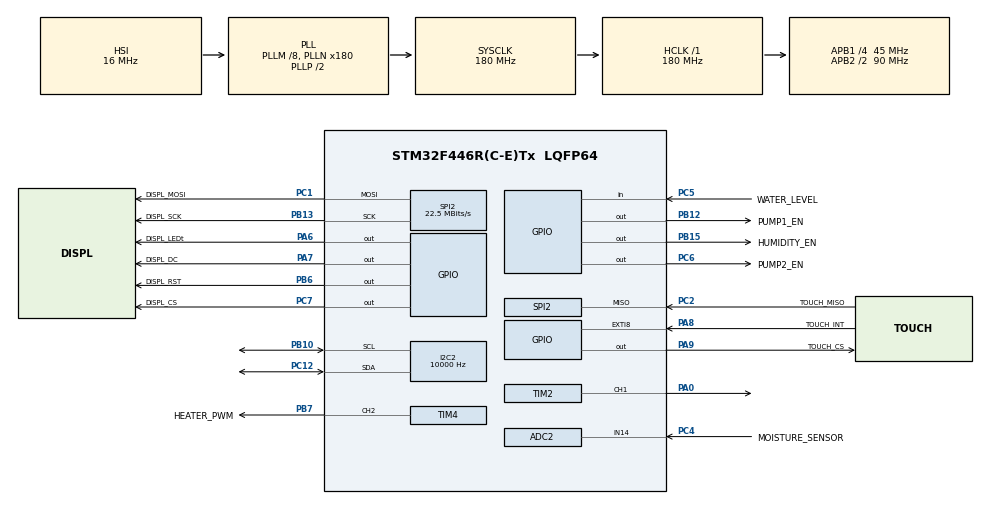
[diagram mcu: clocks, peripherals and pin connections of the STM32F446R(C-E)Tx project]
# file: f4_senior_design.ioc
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ADC2.Channel-0\#ChannelRegularConversion=ADC_CHANNEL_14
ADC2.ContinuousConvMode=ENABLE
ADC2.InjNumberOfConversion=0
ADC2.NbrOfConversionFlag=1
ADC2.Rank-0\#ChannelRegularConversion=1
ADC2.SamplingTime-0\#ChannelRegularConversion=ADC_SAMPLETIME_3CYCLES
Dma.ADC2.1.Direction=DMA_PERIPH_TO_MEMORY
Dma.ADC2.1.FIFOMode=DMA_FIFOMODE_DISABLE
Dma.ADC2.1.Instance=DMA2_Stream2
Dma.ADC2.1.MemDataAlignment=DMA_MDATAALIGN_HALFWORD
Dma.ADC2.1.MemInc=DMA_MINC_ENABLE
Dma.ADC2.1.Mode=DMA_CIRCULAR
Dma.ADC2.1.PeriphDataAlignment=DMA_PDATAALIGN_HALFWORD
Dma.ADC2.1.PeriphInc=DMA_PINC_DISABLE
Dma.ADC2.1.Priority=DMA_PRIORITY_LOW
Dma.Request0=SPI2_TX
Dma.Request1=ADC2
Dma.SPI2_TX.0.Direction=DMA_MEMORY_TO_PERIPH
Dma.SPI2_TX.0.FIFOMode=DMA_FIFOMODE_DISABLE
Dma.SPI2_TX.0.Instance=DMA1_Stream4
Dma.SPI2_TX.0.MemDataAlignment=DMA_MDATAALIGN_BYTE
Dma.SPI2_TX.0.MemInc=DMA_MINC_ENABLE
Dma.SPI2_TX.0.Mode=DMA_NORMAL
Dma.SPI2_TX.0.PeriphDataAlignment=DMA_PDATAALIGN_BYTE
Dma.SPI2_TX.0.PeriphInc=DMA_PINC_DISABLE
Dma.SPI2_TX.0.Priority=DMA_PRIORITY_LOW
I2C2.ClockSpeed=10000
I2C2.I2C_Mode=I2C_Standard
Mcu.Family=STM32F4
Mcu.Name=STM32F446R(C-E)Tx
Mcu.Package=LQFP64
NVIC.DMA1_Stream4_IRQn=true\:0\:0\:false\:false\:true\:false\:true\:true
NVIC.DMA2_Stream2_IRQn=true\:0\:0\:false\:false\:true\:false\:true\:true
NVIC.EXTI9_5_IRQn=true\:0\:0\:false\:false\:true\:true\:true\:true
NVIC.PriorityGroup=NVIC_PRIORITYGROUP_4
NVIC.SPI2_IRQn=true\:0\:0\:false\:false\:true\:true\:true\:true
NVIC.TIM3_IRQn=true\:0\:0\:false\:false\:true\:true\:true\:true
NVIC.TIM4_IRQn=true\:0\:0\:false\:false\:true\:true\:true\:true
PA0-WKUP.Signal=S_TIM2_CH1_ETR
PA13.GPIO_Label=TMS
PA13.Mode=Serial_Wire
PA13.Signal=SYS_JTMS-SWDIO
PA14.GPIO_Label=TCK
PA14.Mode=Serial_Wire
PA14.Signal=SYS_JTCK-SWCLK
PA6.GPIO_Label=DISPL_LED\t
PA6.Signal=GPIO_Output
PA7.GPIO_Label=DISPL_DC
PA7.Signal=GPIO_Output
PA8.GPIO_Label=TOUCH_INT
PA8.GPIO_ModeDefaultEXTI=GPIO_MODE_IT_FALLING
PA8.GPIO_PuPd=GPIO_PULLUP
PA8.Signal=GPXTI8
PA9.GPIO_Label=TOUCH_CS
PA9.PinState=GPIO_PIN_SET
PA9.Signal=GPIO_Output
PB10.GPIO_Pu=GPIO_NOPULL
PB10.Mode=I2C
PB10.Signal=I2C2_SCL
PB12.GPIO_Label=PUMP1_EN
PB12.Signal=GPIO_Output
PB13.GPIO_Label=DISPL_SCK
PB13.Mode=Full_Duplex_Master
PB13.Signal=SPI2_SCK
PB15.GPIO_Label=HUMIDITY_EN
PB15.Signal=GPIO_Output
PB6.GPIO_Label=DISPL_RST
PB6.Signal=GPIO_Output
PB7.GPIO_Label=HEATER_PWM
PB7.Signal=S_TIM4_CH2
PB8.Signal=I2C1_SCL
PB9.Signal=I2C1_SDA
PC1.GPIO_Label=DISPL_MOSI
PC1.Mode=Full_Duplex_Master
PC1.Signal=SPI2_MOSI
PC12.GPIO_Pu=GPIO_NOPULL
PC12.Mode=I2C
PC12.Signal=I2C2_SDA
PC14-OSC32_IN.Mode=LSE-External-Oscillator
PC14-OSC32_IN.Signal=RCC_OSC32_IN
PC15-OSC32_OUT.Mode=LSE-External-Oscillator
PC15-OSC32_OUT.Signal=RCC_OSC32_OUT
PC2.GPIO_Label=TOUCH_MISO
PC2.Mode=Full_Duplex_Master
PC2.Signal=SPI2_MISO
PC4.GPIO_Label=MOISTURE_SENSOR
PC4.Signal=ADCx_IN14
PC5.GPIO_Label=WATER_LEVEL
PC5.Signal=GPIO_Input
PC6.GPIO_Label=PUMP2_EN
PC6.GPIO_Speed=GPIO_SPEED_FREQ_LOW
PC6.Signal=GPIO_Output
PC7.GPIO_Label=DISPL_CS
PC7.PinState=GPIO_PIN_SET
PC7.Signal=GPIO_Output
ProjectManager.HeapSize=0x200
ProjectManager.StackSize=0x400
ProjectManager.TargetToolchain=STM32CubeIDE
RCC.AHBFreq_Value=180000000
RCC.APB1CLKDivider=RCC_HCLK_DIV4
RCC.APB1Freq_Value=45000000
RCC.APB1TimFreq_Value=90000000
RCC.APB2CLKDivider=RCC_HCLK_DIV2
RCC.APB2Freq_Value=90000000
RCC.APB2TimFreq_Value=180000000
RCC.CortexFreq_Value=180000000
RCC.FLatency-AdvancedSettings=FLASH_LATENCY_5
RCC.HCLKFreq_Value=180000000
RCC.HSE_VALUE=8000000
RCC.HSI_VALUE=16000000
RCC.PLLM=8
RCC.PLLN=180
RCC.SYSCLKFreq_VALUE=180000000
RCC.SYSCLKSource=RCC_SYSCLKSOURCE_PLLCLK
RCC.USBFreq_Value=180000000
RCC.VCOOutputFreq_Value=360000000
SH.ADCx_IN14.0=ADC2_IN14,IN14
SH.S_TIM2_CH1_ETR.0=TIM2_CH1,PWM Generation1 CH1
SH.S_TIM4_CH2.0=TIM4_CH2,PWM Generation2 CH2
SPI2.BaudRatePrescaler=SPI_BAUDRATEPRESCALER_2
SPI2.CalculateBaudRate=22.5 MBits/s
SPI2.Direction=SPI_DIRECTION_2LINES
SPI2.Mode=SPI_MODE_MASTER
SPI2.VirtualType=VM_MASTER
STMicroelectronics.X-CUBE-TOUCHGFX.4.24.2.ApplicationCcGraphicsJjApplication=TouchGFXOoGenerator
STMicroelectronics.X-CUBE-TOUCHGFX.4.24.2.tgfx_block_size=2880
STMicroelectronics.X-CUBE-TOUCHGFX.4.24.2.tgfx_buffering_strategy=Partial
STMicroelectronics.X-CUBE-TOUCHGFX.4.24.2.tgfx_custom_height=480
STMicroelectronics.X-CUBE-TOUCHGFX.4.24.2.tgfx_custom_width=320
STMicroelectronics.X-CUBE-TOUCHGFX.4.24.2_IsPackSelfContextualization=true
TIM2.Channel-PWM\ Generation1\ CH1=TIM_CHANNEL_1
TIM2.Period=29999
TIM2.Prescaler=59999
TIM3.Period=299
TIM3.Prescaler=9999
TIM4.Channel-PWM\ Generation2\ CH2=TIM_CHANNEL_2
TIM4.Period=19
TIM4.Prescaler=44999
VP_CRC_VS_CRC.Mode=CRC_Activate
VP_STMicroelectronics.X-CUBE-TOUCHGFX_VS_GraphicsJjApplication_4.24.2.Mode=GraphicsJjApplication
VP_TIM2_VS_ClockSourceINT.Mode=Internal
VP_TIM3_VS_ClockSourceINT.Mode=Internal
VP_TIM4_VS_ClockSourceINT.Mode=Internal
board=NUCLEO-F446RE

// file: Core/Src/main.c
/* USER CODE BEGIN Header */
	/**
	  ******************************************************************************
	  * @file           : main.c
	  * @brief          : Main program body
	  ******************************************************************************
	  * @attention
	  *
	  * Copyright (c) 2025 STMicroelectronics.
	  * All rights reserved.
	  *
	  * This software is licensed under terms that can be found in the LICENSE file
	  * in the root directory of this software component.
	  * If no LICENSE file comes with this software, it is provided AS-IS.
	  *
	  ******************************************************************************
	  */
/* USER CODE END Header */
#include "main.h"
#include "app_touchgfx.h"

ADC_HandleTypeDef hadc2;
DMA_HandleTypeDef hdma_adc2;

CRC_HandleTypeDef hcrc;

I2C_HandleTypeDef hi2c2;

SPI_HandleTypeDef hspi2;
DMA_HandleTypeDef hdma_spi2_tx;

TIM_HandleTypeDef htim2;
TIM_HandleTypeDef htim3;
TIM_HandleTypeDef htim4;

/* USER CODE BEGIN PV */
	uint32_t value_adc;
	float raw_temp;
	float raw_hum;
	float temp;
	float hum;
	float temp_set_point = 20;
	float humidity_set_point = 50;
	int lights_set_point = 8;
	uint8_t i2c_return[8];
	uint8_t i2c_buffer[3] = {0x03, 0x00, 0x04};

/* USER CODE END PV */

void SystemClock_Config(void);
static void MX_GPIO_Init(void);
static void MX_DMA_Init(void);
static void MX_SPI2_Init(void);
static void MX_CRC_Init(void);
static void MX_TIM3_Init(void);
static void MX_TIM2_Init(void);
static void MX_I2C2_Init(void);
static void MX_TIM4_Init(void);
static void MX_ADC2_Init(void);

int main(void)
{

  /* MCU Configuration--------------------------------------------------------*/

  /* Reset of all peripherals, Initializes the Flash interface and the Systick. */
  HAL_Init();

  /* Configure the system clock */
  SystemClock_Config();

  /* Initialize all configured peripherals */
  MX_GPIO_Init();
  MX_DMA_Init();
  MX_SPI2_Init();
  MX_CRC_Init();
  MX_TIM3_Init();
  MX_TIM2_Init();
  MX_I2C2_Init();
  MX_TIM4_Init();
  MX_ADC2_Init();
  MX_TouchGFX_Init();
  /* USER CODE BEGIN 2 */

	  HAL_TIM_PWM_Init(&htim2);

	  Displ_Init(Displ_Orientat_0);			// initialize display controller - set orientation parameter as per TouchGFX setup
	  touchgfxSignalVSync();
	  Displ_Init(Displ_Orientat_0);			// initialize display controller - set orientation parameter as per TouchGFX setup
	  touchgfxSignalVSync();

	  Displ_BackLight('I');  					// initialize backlight
	  HAL_TIM_Base_Start_IT(&TGFX_T);			// start TouchGFX tick timer
	  HAL_ADC_Start_DMA(&hadc2,(uint32_t*)&value_adc,1);
	  HAL_TIM_PWM_Start(&htim2,TIM_CHANNEL_1);

	  HAL_TIM_PWM_Start(&htim4, TIM_CHANNEL_2);
	  htim4.Instance->CCR2 = 10;
	  htim2.Instance->CCR1 = 15000;

  /* USER CODE END 2 */

  /* Infinite loop */
  /* USER CODE BEGIN WHILE */
//	  while(HAL_I2C_IsDeviceReady(&hi2c1, 0xB8,1, HAL_MAX_DELAY) != HAL_OK){
//
//	  }

	  //HAL_GPIO_WritePin(HUMIDITY_EN_GPIO_Port, HUMIDITY_EN_Pin,1);

	  while (1)
	  {
//		  HAL_GPIO_WritePin(GPIOA, GPIO_PIN_0,1);
//		  HAL_GPIO_WritePin(PUMP1_EN_GPIO_Port, PUMP1_EN_Pin, 0);
//		  HAL_GPIO_WritePin(PUMP2_EN_GPIO_Port, PUMP2_EN_Pin, 0);
//	  	  HAL_GPIO_WritePin(HUMIDITY_EN_GPIO_Port, HUMIDITY_EN_Pin,0);
//
//		  HAL_Delay(10000);
//		  HAL_GPIO_WritePin(PUMP1_EN_GPIO_Port, PUMP1_EN_Pin, 1);
//		  HAL_GPIO_WritePin(PUMP2_EN_GPIO_Port, PUMP2_EN_Pin, 1);
//	  	  HAL_GPIO_WritePin(HUMIDITY_EN_GPIO_Port, HUMIDITY_EN_Pin,1);
//
//		  HAL_Delay(10000);

		  if (HAL_GPIO_ReadPin(WATER_LEVEL_GPIO_Port, WATER_LEVEL_Pin)){
			  HAL_GPIO_WritePin(PUMP1_EN_GPIO_Port, PUMP1_EN_Pin, 1);
			  HAL_GPIO_WritePin(PUMP2_EN_GPIO_Port, PUMP2_EN_Pin, 1);
		  }
		  else{
			  HAL_GPIO_WritePin(PUMP1_EN_GPIO_Port, PUMP1_EN_Pin, 0);
			  HAL_GPIO_WritePin(PUMP2_EN_GPIO_Port, PUMP2_EN_Pin, 0);
		  }

		  HAL_ADC_Start_DMA(&hadc2,(uint32_t*)&value_adc,1); //Read Soil Moisture

		  HAL_I2C_Master_Transmit (&hi2c2, 0xB8, i2c_buffer, 3, 100);
		  HAL_I2C_Master_Receive (&hi2c2, 0xB9, i2c_return, 8, 100);

		  temp = ((i2c_return[4] << 8) + i2c_return[5]);
		  hum = ((i2c_return[2] << 8) + i2c_return[3]);
		  temp = floor(temp)/10.0;
		  hum = floor(hum)/10.0;

//		  raw_temp = ((i2c_return[4] << 8) + i2c_return[5]);
//		  raw_hum = ((i2c_return[2] << 8) + i2c_return[3]);
//		  raw_temp = floor(raw_temp)/10.0;
//		  raw_hum = floor(raw_hum)/10.0;
//
//		  if (raw_temp > 0 && raw_temp < 100){
//			  temp = raw_temp;
//		  }
//
//		  if (raw_hum > 0 && raw_hum < 100){
//		  			  hum = raw_hum;
//		  		  }

		  if (hum <=(40)){
			  HAL_GPIO_WritePin(HUMIDITY_EN_GPIO_Port, HUMIDITY_EN_Pin,1);
		  }
		  if (hum >=(60)){
			  HAL_GPIO_WritePin(HUMIDITY_EN_GPIO_Port, HUMIDITY_EN_Pin,0);
			  }
//
//		  //htim4.Instance->CCR2 = (value_adc/4096.0) * 100;
//		  if (temp < 23){
//			  htim4.Instance->CCR2 = 10;
//		  }
//		  if (temp > 24){
//			  htim4.Instance->CCR2 = 0;
//		  		  }
////		  else{
////			  htim2.Instance->CCR1 = 0;
////
////		  }
//		  //HAL_GPIO_WritePin(GPIOA, GPIO_PIN_10,1);
//

//
//	//	  for (int i = 0; i <= 8; i++){
//	//		  htim2.Instance->CCR1 = 4096 - (512 * i); //100
//	//		  HAL_Delay(2000);
//	//
//	//	  }
//
//		  //HAL_Delay(100);
//		  //HAL_I2C_Master_Receive (&hi2c2, 0xB9, data, 5, 100);
//
//		  //HAL_I2C_Mem_Read (&hi2c2, 0xB8, 0x00, 0, value_humidity_high, 5, 1000);
//		  //HAL_I2C_Master_Transmit (I2C_HandleTypeDef * hi2c, uint16_t DevAddress, uint8_t* pData, uint16_t Size, uint32_t Timeout);
//		  //HAL_I2C_Master_Receive (I2C_HandleTypeDef * hi2c, uint16_t DevAddress, uint8_t* pData, uint16_t Size, uint32_t Timeout);
//	//	  HAL_I2C_Mem_Write (I2C_HandleTypeDef * hi2c, uint16_t DevAddress, uint16_t MemAddress, uint16_t MemAddSize, uint8_t * pData, uint16_t Size, uint32_t Timeout);
//
//
//		  //HAL_I2C_Mem_Read (I2C_HandleTypeDef * hi2c, uint16_t DevAddress, uint16_t MemAddress, uint16_t MemAddSize, uint8_t * pData, uint16_t Size, uint32_t Timeout);
//
//
//
    /* USER CODE END WHILE */

  MX_TouchGFX_Process();
	  }
}

void SystemClock_Config(void)
{
  RCC_OscInitTypeDef RCC_OscInitStruct = {0};
  RCC_ClkInitTypeDef RCC_ClkInitStruct = {0};

  /** Configure the main internal regulator output voltage
  */
  __HAL_RCC_PWR_CLK_ENABLE();
  __HAL_PWR_VOLTAGESCALING_CONFIG(PWR_REGULATOR_VOLTAGE_SCALE1);

  /** Initializes the RCC Oscillators according to the specified parameters
  * in the RCC_OscInitTypeDef structure.
  */
  RCC_OscInitStruct.OscillatorType = RCC_OSCILLATORTYPE_HSI;
  RCC_OscInitStruct.HSIState = RCC_HSI_ON;
  RCC_OscInitStruct.HSICalibrationValue = RCC_HSICALIBRATION_DEFAULT;
  RCC_OscInitStruct.PLL.PLLState = RCC_PLL_ON;
  RCC_OscInitStruct.PLL.PLLSource = RCC_PLLSOURCE_HSI;
  RCC_OscInitStruct.PLL.PLLM = 8;
  RCC_OscInitStruct.PLL.PLLN = 180;
  RCC_OscInitStruct.PLL.PLLP = RCC_PLLP_DIV2;
  RCC_OscInitStruct.PLL.PLLQ = 2;
  RCC_OscInitStruct.PLL.PLLR = 2;
  if (HAL_RCC_OscConfig(&RCC_OscInitStruct) != HAL_OK)
  {
    Error_Handler();
  }

  /** Activate the Over-Drive mode
  */
  if (HAL_PWREx_EnableOverDrive() != HAL_OK)
  {
    Error_Handler();
  }

  /** Initializes the CPU, AHB and APB buses clocks
  */
  RCC_ClkInitStruct.ClockType = RCC_CLOCKTYPE_HCLK|RCC_CLOCKTYPE_SYSCLK
                              |RCC_CLOCKTYPE_PCLK1|RCC_CLOCKTYPE_PCLK2;
  RCC_ClkInitStruct.SYSCLKSource = RCC_SYSCLKSOURCE_PLLCLK;
  RCC_ClkInitStruct.AHBCLKDivider = RCC_SYSCLK_DIV1;
  RCC_ClkInitStruct.APB1CLKDivider = RCC_HCLK_DIV4;
  RCC_ClkInitStruct.APB2CLKDivider = RCC_HCLK_DIV2;

  if (HAL_RCC_ClockConfig(&RCC_ClkInitStruct, FLASH_LATENCY_5) != HAL_OK)
  {
    Error_Handler();
  }
}

static void MX_ADC2_Init(void)
{

  ADC_ChannelConfTypeDef sConfig = {0};

  /** Configure the global features of the ADC (Clock, Resolution, Data Alignment and number of conversion)
  */
  hadc2.Instance = ADC2;
  hadc2.Init.ClockPrescaler = ADC_CLOCK_SYNC_PCLK_DIV4;
  hadc2.Init.Resolution = ADC_RESOLUTION_12B;
  hadc2.Init.ScanConvMode = DISABLE;
  hadc2.Init.ContinuousConvMode = ENABLE;
  hadc2.Init.DiscontinuousConvMode = DISABLE;
  hadc2.Init.ExternalTrigConvEdge = ADC_EXTERNALTRIGCONVEDGE_NONE;
  hadc2.Init.ExternalTrigConv = ADC_SOFTWARE_START;
  hadc2.Init.DataAlign = ADC_DATAALIGN_RIGHT;
  hadc2.Init.NbrOfConversion = 1;
  hadc2.Init.DMAContinuousRequests = DISABLE;
  hadc2.Init.EOCSelection = ADC_EOC_SINGLE_CONV;
  if (HAL_ADC_Init(&hadc2) != HAL_OK)
  {
    Error_Handler();
  }

  /** Configure for the selected ADC regular channel its corresponding rank in the sequencer and its sample time.
  */
  sConfig.Channel = ADC_CHANNEL_14;
  sConfig.Rank = 1;
  sConfig.SamplingTime = ADC_SAMPLETIME_3CYCLES;
  if (HAL_ADC_ConfigChannel(&hadc2, &sConfig) != HAL_OK)
  {
    Error_Handler();
  }

}

static void MX_CRC_Init(void)
{

  hcrc.Instance = CRC;
  if (HAL_CRC_Init(&hcrc) != HAL_OK)
  {
    Error_Handler();
  }

}

static void MX_I2C2_Init(void)
{

  hi2c2.Instance = I2C2;
  hi2c2.Init.ClockSpeed = 100000;
  hi2c2.Init.DutyCycle = I2C_DUTYCYCLE_2;
  hi2c2.Init.OwnAddress1 = 0;
  hi2c2.Init.AddressingMode = I2C_ADDRESSINGMODE_7BIT;
  hi2c2.Init.DualAddressMode = I2C_DUALADDRESS_DISABLE;
  hi2c2.Init.OwnAddress2 = 0;
  hi2c2.Init.GeneralCallMode = I2C_GENERALCALL_DISABLE;
  hi2c2.Init.NoStretchMode = I2C_NOSTRETCH_DISABLE;
  if (HAL_I2C_Init(&hi2c2) != HAL_OK)
  {
    Error_Handler();
  }

}

static void MX_SPI2_Init(void)
{

  /* SPI2 parameter configuration*/
  hspi2.Instance = SPI2;
  hspi2.Init.Mode = SPI_MODE_MASTER;
  hspi2.Init.Direction = SPI_DIRECTION_2LINES;
  hspi2.Init.DataSize = SPI_DATASIZE_8BIT;
  hspi2.Init.CLKPolarity = SPI_POLARITY_LOW;
  hspi2.Init.CLKPhase = SPI_PHASE_1EDGE;
  hspi2.Init.NSS = SPI_NSS_SOFT;
  hspi2.Init.BaudRatePrescaler = SPI_BAUDRATEPRESCALER_2;
  hspi2.Init.FirstBit = SPI_FIRSTBIT_MSB;
  hspi2.Init.TIMode = SPI_TIMODE_DISABLE;
  hspi2.Init.CRCCalculation = SPI_CRCCALCULATION_DISABLE;
  hspi2.Init.CRCPolynomial = 10;
  if (HAL_SPI_Init(&hspi2) != HAL_OK)
  {
    Error_Handler();
  }

}

static void MX_TIM2_Init(void)
{

  TIM_ClockConfigTypeDef sClockSourceConfig = {0};
  TIM_MasterConfigTypeDef sMasterConfig = {0};
  TIM_OC_InitTypeDef sConfigOC = {0};

  htim2.Instance = TIM2;
  htim2.Init.Prescaler = 59999;
  htim2.Init.CounterMode = TIM_COUNTERMODE_UP;
  htim2.Init.Period = 29999;
  htim2.Init.ClockDivision = TIM_CLOCKDIVISION_DIV1;
  htim2.Init.AutoReloadPreload = TIM_AUTORELOAD_PRELOAD_DISABLE;
  if (HAL_TIM_Base_Init(&htim2) != HAL_OK)
  {
    Error_Handler();
  }
  sClockSourceConfig.ClockSource = TIM_CLOCKSOURCE_INTERNAL;
  if (HAL_TIM_ConfigClockSource(&htim2, &sClockSourceConfig) != HAL_OK)
  {
    Error_Handler();
  }
  if (HAL_TIM_PWM_Init(&htim2) != HAL_OK)
  {
    Error_Handler();
  }
  sMasterConfig.MasterOutputTrigger = TIM_TRGO_RESET;
  sMasterConfig.MasterSlaveMode = TIM_MASTERSLAVEMODE_DISABLE;
  if (HAL_TIMEx_MasterConfigSynchronization(&htim2, &sMasterConfig) != HAL_OK)
  {
    Error_Handler();
  }
  sConfigOC.OCMode = TIM_OCMODE_PWM1;
  sConfigOC.Pulse = 0;
  sConfigOC.OCPolarity = TIM_OCPOLARITY_HIGH;
  sConfigOC.OCFastMode = TIM_OCFAST_DISABLE;
  if (HAL_TIM_PWM_ConfigChannel(&htim2, &sConfigOC, TIM_CHANNEL_1) != HAL_OK)
  {
    Error_Handler();
  }
  HAL_TIM_MspPostInit(&htim2);

}

static void MX_TIM3_Init(void)
{

  TIM_ClockConfigTypeDef sClockSourceConfig = {0};
  TIM_MasterConfigTypeDef sMasterConfig = {0};

  htim3.Instance = TIM3;
  htim3.Init.Prescaler = 9999;
  htim3.Init.CounterMode = TIM_COUNTERMODE_UP;
  htim3.Init.Period = 299;
  htim3.Init.ClockDivision = TIM_CLOCKDIVISION_DIV1;
  htim3.Init.AutoReloadPreload = TIM_AUTORELOAD_PRELOAD_DISABLE;
  if (HAL_TIM_Base_Init(&htim3) != HAL_OK)
  {
    Error_Handler();
  }
  sClockSourceConfig.ClockSource = TIM_CLOCKSOURCE_INTERNAL;
  if (HAL_TIM_ConfigClockSource(&htim3, &sClockSourceConfig) != HAL_OK)
  {
    Error_Handler();
  }
  sMasterConfig.MasterOutputTrigger = TIM_TRGO_RESET;
  sMasterConfig.MasterSlaveMode = TIM_MASTERSLAVEMODE_DISABLE;
  if (HAL_TIMEx_MasterConfigSynchronization(&htim3, &sMasterConfig) != HAL_OK)
  {
    Error_Handler();
  }

}

static void MX_TIM4_Init(void)
{

  TIM_ClockConfigTypeDef sClockSourceConfig = {0};
  TIM_MasterConfigTypeDef sMasterConfig = {0};
  TIM_OC_InitTypeDef sConfigOC = {0};

  htim4.Instance = TIM4;
  htim4.Init.Prescaler = 44999;
  htim4.Init.CounterMode = TIM_COUNTERMODE_UP;
  htim4.Init.Period = 19;
  htim4.Init.ClockDivision = TIM_CLOCKDIVISION_DIV1;
  htim4.Init.AutoReloadPreload = TIM_AUTORELOAD_PRELOAD_DISABLE;
  if (HAL_TIM_Base_Init(&htim4) != HAL_OK)
  {
    Error_Handler();
  }
  sClockSourceConfig.ClockSource = TIM_CLOCKSOURCE_INTERNAL;
  if (HAL_TIM_ConfigClockSource(&htim4, &sClockSourceConfig) != HAL_OK)
  {
    Error_Handler();
  }
  if (HAL_TIM_PWM_Init(&htim4) != HAL_OK)
  {
    Error_Handler();
  }
  sMasterConfig.MasterOutputTrigger = TIM_TRGO_RESET;
  sMasterConfig.MasterSlaveMode = TIM_MASTERSLAVEMODE_DISABLE;
  if (HAL_TIMEx_MasterConfigSynchronization(&htim4, &sMasterConfig) != HAL_OK)
  {
    Error_Handler();
  }
  sConfigOC.OCMode = TIM_OCMODE_PWM1;
  sConfigOC.Pulse = 0;
  sConfigOC.OCPolarity = TIM_OCPOLARITY_HIGH;
  sConfigOC.OCFastMode = TIM_OCFAST_DISABLE;
  if (HAL_TIM_PWM_ConfigChannel(&htim4, &sConfigOC, TIM_CHANNEL_2) != HAL_OK)
  {
    Error_Handler();
  }
  HAL_TIM_MspPostInit(&htim4);

}

static void MX_DMA_Init(void)
{

  /* DMA controller clock enable */
  __HAL_RCC_DMA1_CLK_ENABLE();
  __HAL_RCC_DMA2_CLK_ENABLE();

  /* DMA interrupt init */
  /* DMA1_Stream4_IRQn interrupt configuration */
  HAL_NVIC_SetPriority(DMA1_Stream4_IRQn, 0, 0);
  HAL_NVIC_EnableIRQ(DMA1_Stream4_IRQn);
  /* DMA2_Stream2_IRQn interrupt configuration */
  HAL_NVIC_SetPriority(DMA2_Stream2_IRQn, 0, 0);
  HAL_NVIC_EnableIRQ(DMA2_Stream2_IRQn);

}

static void MX_GPIO_Init(void)
{
  GPIO_InitTypeDef GPIO_InitStruct = {0};

  /* GPIO Ports Clock Enable */
  __HAL_RCC_GPIOC_CLK_ENABLE();
  __HAL_RCC_GPIOA_CLK_ENABLE();
  __HAL_RCC_GPIOB_CLK_ENABLE();

  /*Configure GPIO pin Output Level */
  HAL_GPIO_WritePin(GPIOA, DISPL_LED_Pin|DISPL_DC_Pin, GPIO_PIN_RESET);

  /*Configure GPIO pin Output Level */
  HAL_GPIO_WritePin(GPIOB, PUMP1_EN_Pin|HUMIDITY_EN_Pin|DISPL_RST_Pin, GPIO_PIN_RESET);

  /*Configure GPIO pin Output Level */
  HAL_GPIO_WritePin(PUMP2_EN_GPIO_Port, PUMP2_EN_Pin, GPIO_PIN_RESET);

  /*Configure GPIO pin Output Level */
  HAL_GPIO_WritePin(DISPL_CS_GPIO_Port, DISPL_CS_Pin, GPIO_PIN_SET);

  /*Configure GPIO pin Output Level */
  HAL_GPIO_WritePin(TOUCH_CS_GPIO_Port, TOUCH_CS_Pin, GPIO_PIN_SET);

  /*Configure GPIO pins : DISPL_LED_Pin DISPL_DC_Pin TOUCH_CS_Pin */
  GPIO_InitStruct.Pin = DISPL_LED_Pin|DISPL_DC_Pin|TOUCH_CS_Pin;
  GPIO_InitStruct.Mode = GPIO_MODE_OUTPUT_PP;
  GPIO_InitStruct.Pull = GPIO_NOPULL;
  GPIO_InitStruct.Speed = GPIO_SPEED_FREQ_LOW;
  HAL_GPIO_Init(GPIOA, &GPIO_InitStruct);

  /*Configure GPIO pin : WATER_LEVEL_Pin */
  GPIO_InitStruct.Pin = WATER_LEVEL_Pin;
  GPIO_InitStruct.Mode = GPIO_MODE_INPUT;
  GPIO_InitStruct.Pull = GPIO_NOPULL;
  HAL_GPIO_Init(WATER_LEVEL_GPIO_Port, &GPIO_InitStruct);

  /*Configure GPIO pins : PUMP1_EN_Pin HUMIDITY_EN_Pin DISPL_RST_Pin */
  GPIO_InitStruct.Pin = PUMP1_EN_Pin|HUMIDITY_EN_Pin|DISPL_RST_Pin;
  GPIO_InitStruct.Mode = GPIO_MODE_OUTPUT_PP;
  GPIO_InitStruct.Pull = GPIO_NOPULL;
  GPIO_InitStruct.Speed = GPIO_SPEED_FREQ_LOW;
  HAL_GPIO_Init(GPIOB, &GPIO_InitStruct);

  /*Configure GPIO pins : PUMP2_EN_Pin DISPL_CS_Pin */
  GPIO_InitStruct.Pin = PUMP2_EN_Pin|DISPL_CS_Pin;
  GPIO_InitStruct.Mode = GPIO_MODE_OUTPUT_PP;
  GPIO_InitStruct.Pull = GPIO_NOPULL;
  GPIO_InitStruct.Speed = GPIO_SPEED_FREQ_LOW;
  HAL_GPIO_Init(GPIOC, &GPIO_InitStruct);

  /*Configure GPIO pin : TOUCH_INT_Pin */
  GPIO_InitStruct.Pin = TOUCH_INT_Pin;
  GPIO_InitStruct.Mode = GPIO_MODE_IT_FALLING;
  GPIO_InitStruct.Pull = GPIO_PULLUP;
  HAL_GPIO_Init(TOUCH_INT_GPIO_Port, &GPIO_InitStruct);

  /*Configure GPIO pins : PB8 PB9 */
  GPIO_InitStruct.Pin = GPIO_PIN_8|GPIO_PIN_9;
  GPIO_InitStruct.Mode = GPIO_MODE_AF_OD;
  GPIO_InitStruct.Pull = GPIO_NOPULL;
  GPIO_InitStruct.Speed = GPIO_SPEED_FREQ_VERY_HIGH;
  GPIO_InitStruct.Alternate = GPIO_AF4_I2C1;
  HAL_GPIO_Init(GPIOB, &GPIO_InitStruct);

  /* EXTI interrupt init*/
  HAL_NVIC_SetPriority(EXTI9_5_IRQn, 0, 0);
  HAL_NVIC_EnableIRQ(EXTI9_5_IRQn);

}

/* USER CODE BEGIN 4 */
	void HAL_TIM_PeriodElapsedCallback(TIM_HandleTypeDef *htim)
	{
	  // Check which version of the timer triggered this callback and toggle LED
		if (htim==&TGFX_T){
			  //Displ_Init(Displ_Orientat_0);			// initialize display controller - set orientation parameter as per TouchGFX setup
			  touchgfxSignalVSync();
		}
	}
/* USER CODE END 4 */

void Error_Handler(void)
{
	  __disable_irq();
	  while (1)
	  {
	  }
}
